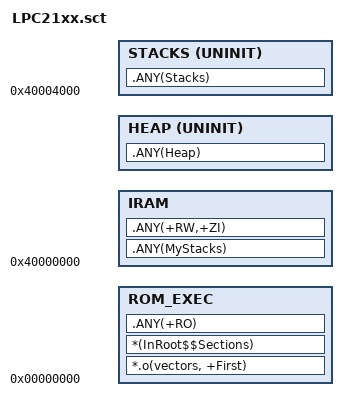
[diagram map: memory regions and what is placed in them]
; *************************************************************
; *** Scatter-Loading Description File generated by TKStudio***
; *************************************************************
; write by yuanguiyou 2008/4/23 
; for other project you musth change the "STACKS 0x40002000 UNINIT"
; WITH REPLACE IT use the CPU bigest RAM LONG ADDRESS

ROM_LOAD 0x00000000
{
    ROM_EXEC 0x00000000 
    {
        *.o(vectors, +First)
        *(InRoot$$Sections)
       .ANY(+RO)
    }

    IRAM 0x40000000 
    {
        .ANY(MyStacks)
        .ANY(+RW,+ZI)
    }

    HEAP +0 UNINIT
    {
        .ANY(Heap)
    }

    STACKS 0x40004000 UNINIT 
    {
        .ANY(Stacks)
    }
}
